# NANO112AN_v1 register map
File version: 1.0
Registers are 32-bit, read-write, reset 0x0 unless marked. A register's access mark holds for its fields unless they carry their own. Offsets are from the block's base; [hi:lo] are bit positions; {n}, {i} and the like mark numbered series; 'fields as' and 'values as' point back to an identical list.

## DMA_GCR — PDMA Register Map
Base 0x50008F00
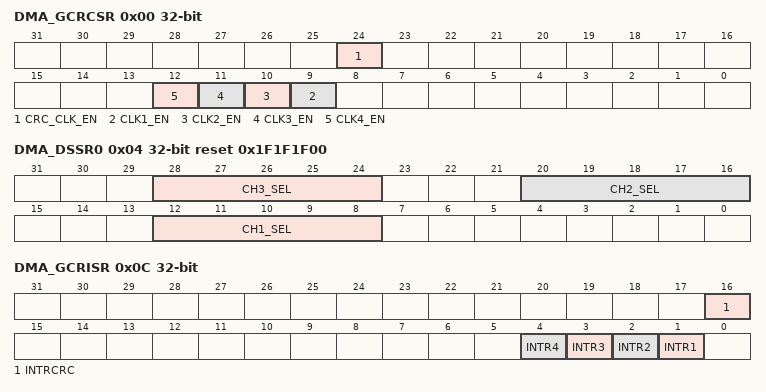
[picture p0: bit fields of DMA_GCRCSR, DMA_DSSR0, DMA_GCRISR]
0x00 DMA_GCRCSR — DMA Global Control Register
  [all] fields
    0=Disabled; 1=Enabled
  [24] CRC_CLK_EN — CRC Controller Clock Enable Control
  [n+8] CLK{n}_EN (n=1..4) — PDMA Controller Channel {n} Clock Enable Control
0x04 DMA_DSSR0 reset 0x1F1F1F00 — DMA Service Selection Control Register 0
  [28:24] CH3_SEL — Channel 3 Selection. This filed defines which peripheral is connected to PDMA channel 3. User can configure the peripheral setting by CH3_SEL. The channel configuration is the same as CH1_SEL field. Please refer to the explanation of CH1_SEL.
  [20:16] CH2_SEL — Channel 2 Selection. This filed defines which peripheral is connected to PDMA channel 2. User can configure the peripheral setting by CH2_SEL. The channel configuration is the same as CH1_SEL field. Please refer to the explanation of CH1_SEL.
  [12:8] CH1_SEL — Channel 1 Selection. This filed defines which peripheral is connected to PDMA channel 1. User can configure the peripheral by setting CH1_SEL.
    0=Connect to SPI0_TX; 1=Connect to SPI1_TX; 2=Connect to UART0_TX; 3=Connect to UART1_TX; {v}=Connect to TMR{v-9} (v=9..12); 16=Connect to SPI0_RX; 17=Connect to SPI1_RX; 18=Connect to UART0_RX; 19=Connect to UART1_RX; 22=Connect to ADC; 25=Connect to PWM0_CH0; 26=Connect to PWM0_CH2
0x08 DMA_DSSR1 reset 0x1F — DMA Service Selection Control Register 1
  [4:0] CH4_SEL — Channel 4 Selection. This filed defines which peripheral is connected to PDMA channel 4. User can configure the peripheral by setting CH4_SEL.
    values as DMA_DSSR0.CH1_SEL
0x0C DMA_GCRISR ro — DMA Global Interrupt Status Register
  [16] INTRCRC — Interrupt Status of CRC Controller (Read Only). This bit is the interrupt status of CRC controller
  [4] INTR4 — Interrupt Status of Channel 4 (Read Only). This bit is the interrupt status of PDMA channel4.
  [3] INTR3 — Interrupt Status of Channel 3 (Read Only). This bit is the interrupt status of PDMA channel3.
  [2] INTR2 — Interrupt Status of Channel 2 (Read Only). This bit is the interrupt status of PDMA channel2. Note: This bit is read only
  [1] INTR1 — Interrupt Status of Channel 1 (Read Only). This bit is the interrupt status of PDMA channel1.

## WDT — WDT Register Map
Base 0x40004000
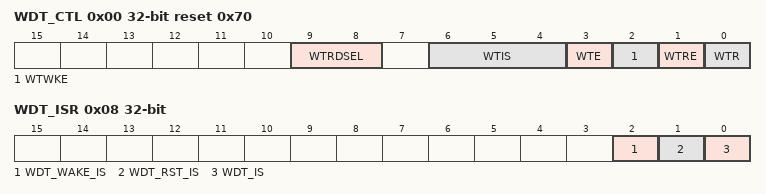
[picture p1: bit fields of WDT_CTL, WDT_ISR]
0x00 WDT_CTL reset 0x70 — Watchdog Timer Control Register
  [9:8] WTRDSEL — Watchdog Timer Reset Delay Select
  [6:4] WTIS — Watchdog Timer Interval Selection (Write Protect). Please refer to open lock sequence to program it. The three bits select the time-out interval for the Watchdog timer. This count is free running counter. Please refer to Table 6 13.
  [3] WTE — Watchdog Timer Enable Control (Write Protect). Please refer to open lock sequence to program it.
    0=Watchdog timer Disabled (this action will reset the internal counter); 1=Watchdog timer Enabled
  [2] WTWKE — Watchdog Timer Wake-up Function Enable Control (Write Protect). Please refer to open lock sequence to program it.
    0=Watchdog timer Wake-up CPU function Disabled; 1=Wake-up function Enabled so that Watchdog timer time-out can wake up CPU from Power-down mode
  [1] WTRE — Watchdog Timer Reset Function Enable Control (Write Protect). Please refer to open lock sequence to program it. Setting this bit will enable the Watchdog timer reset function.
    0=Watchdog timer reset function Disabled; 1=Watchdog timer reset function Enabled
  [0] WTR — Clear Watchdog Timer (Write Protect). Please refer to open lock sequence to program it. Setting this bit will clear the Watchdog timer. Note: This bit will be auto cleared after 1 PCLK clock cycle.
    0=No effect; 1=Reset the contents of the Watchdog timer
0x04 WDT_IER — Watchdog Timer Interrupt Enable Register
  [0] WDT_IE — Watchdog Timer Interrupt Enable Control
    0=Watchdog timer interrupt Disabled; 1=Watchdog timer interrupt Enabled
0x08 WDT_ISR — Watchdog Timer Interrupt Status Register
  [2] WDT_WAKE_IS — Watchdog Timer Wake-up Status. If Watchdog timer causes system to wake up from Power-down mode, this bit will be set to 1. It must be cleared by software with a write "1" to this bit. Note1: When system in Power-down mode and watchdog time-out, hardware will set WDT_WAKE_IS and WDT_IS. Note2: After one engine clock, this bit can be cleared by writing "1" to it
    0=Watchdog timer does not cause system wake-up; 1=Wake system up from Power-down mode by Watchdog time-out
  [1] WDT_RST_IS — Watchdog Timer Reset Status. When the Watchdog timer initiates a reset, the hardware will set this bit. This flag can be read by software to determine the source of reset. Software is responsible to clear it manually by writing "1" to it. If WTRE is disabled, then the Watchdog timer has no effect on this bit. Note: This bit is read only, but can be cleared by writing "1" to it.
    0=Watchdog timer reset did not occur; 1=Watchdog timer reset occurs
  [0] WDT_IS — Watchdog Timer Interrupt Status. If the Watchdog timer interrupt is enabled, then the hardware will set this bit to indicate that the Watchdog timer interrupt has occurred. If the Watchdog timer interrupt is not enabled, then this bit indicates that a time-out period has elapsed. Note: This bit is read only, but can be cleared by writing "1" to it.
    0=Watchdog timer interrupt did not occur; 1=Watchdog timer interrupt occurs

## WWDT — WWDT Register Map
Base 0x40004100
0x00 WWDTRLD wo — Window Watchdog Timer Reload Counter Register
  [31:0] WWDTRLD — Window Watchdog Timer Reload Counter Register. Writing 0x00005AA5 to this register will reload the Window Watchdog Timer counter value to 0x3F. Note: This register can only be written when WWDT counter value between 0 and WINCMP, otherwise WWDT will generate RESET signal.
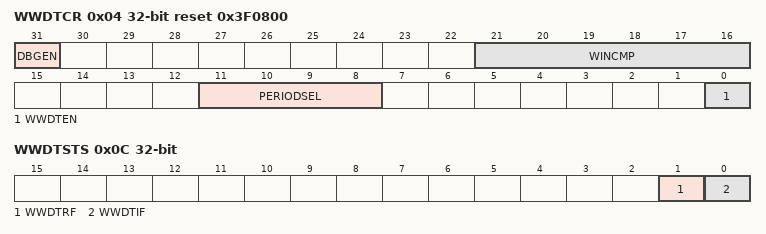
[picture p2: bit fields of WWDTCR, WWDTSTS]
0x04 WWDTCR reset 0x3F0800 — Window Watchdog Timer Control Register
  [31] DBGEN — WWDT Debug Enable Control
    0=WWDT stopped count if system is in Debug mode; 1=WWDT still counted even system is in Debug mode
  [21:16] WINCMP — WWDT Window Compare Register. Set this register to adjust the valid reload window. Note: WWDTRLD register can only be written when WWDT counter value between 0 and WINCMP, otherwise WWDT will generate RESET signal.
  [11:8] PERIODSEL — WWDT Pre-scale Period Select. These three bits select the pre-scale for the WWDT counter period. Please refer to Table 6 14.
  [0] WWDTEN — Window Watchdog Enable Control. Set this bit to enable Window Watchdog timer.
    0=Window Watchdog timer function Disabled; 1=Window Watchdog timer function Enabled
0x08 WWDT_IER — Window Watchdog Timer Interrupt Enable Register
  [0] WWDTIE — WWDT Interrupt Enable Control. Setting this bit will enable the Window Watchdog timer interrupt function.
    0=Watchdog timer interrupt function Disabled; 1=Watchdog timer interrupt function Enabled
0x0C WWDTSTS — Window Watchdog Timer Status Register
  [1] WWDTRF — WWDT Reset Flag. When WWDT counter down count to 0 or write WWDTRLD during WWDT counter larger than WINCMP, chip will be reset and this bit is set to 1. This bit can be cleared by writing one to it.
  [0] WWDTIF — WWDT Compare Match Interrupt Flag. When WWCMP match the WWDT counter, then this bit is set to 1. This bit can be cleared by writing one to it.
0x10 WWDTVAL ro reset 0x3F — Window Watchdog Timer Counter Value Register
  [5:0] WWDTVAL — WWDT Counter Value. This register reflects the current counter value of window watchdog.
